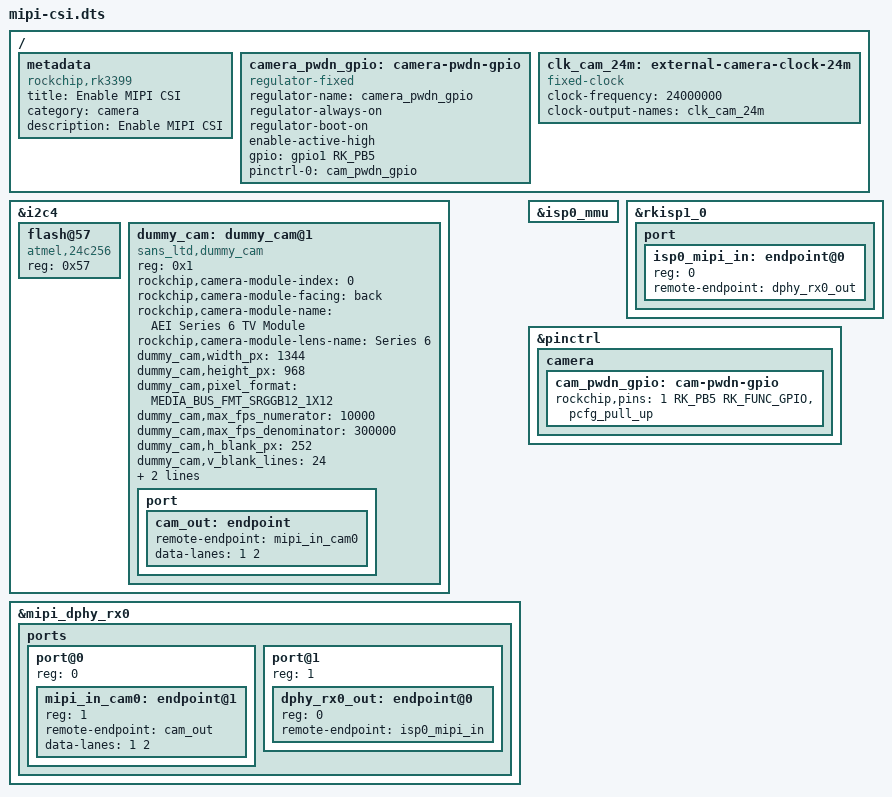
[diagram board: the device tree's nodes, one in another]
/dts-v1/;
/plugin/;

#include <dt-bindings/gpio/gpio.h>
#include <dt-bindings/pinctrl/rockchip.h>
#include <dt-bindings/display/media-bus-format.h>

/ {
	metadata {
		title ="Enable MIPI CSI";
		compatible = "rockchip,rk3399";
		category = "camera";
		description = "Enable MIPI CSI";
	};


	fragment@0 {
		target-path = "/";

		__overlay__ {

			camera_pwdn_gpio: camera-pwdn-gpio {
				status = "okay";
				compatible = "regulator-fixed";
				regulator-name = "camera_pwdn_gpio";
				regulator-always-on;
				regulator-boot-on;
				enable-active-high;
				gpio = <&gpio1 RK_PB5 GPIO_ACTIVE_HIGH>;
				pinctrl-names = "default";
				pinctrl-0 = <&cam_pwdn_gpio>;
			};

			clk_cam_24m: external-camera-clock-24m {
				status = "okay";
				compatible = "fixed-clock";
				clock-frequency = <24000000>;
				clock-output-names = "clk_cam_24m";
				#clock-cells = <0>;
			};
		};
	};

	fragment@1 {
		target = <&i2c4>;

		__overlay__ {
			status = "okay";
			#address-cells = <1>;
			#size-cells = <0>;

/*
			camera_imx219: camera-imx219@10 {
				status = "okay";
				compatible = "sony,imx219";
				reg = <0x10>;

				clocks = <&clk_cam_24m>;
				clock-names = "xvclk";

				rockchip,camera-module-index = <0>;
				rockchip,camera-module-facing = "back";
				rockchip,camera-module-name = "rpi-camera-v2";
				rockchip,camera-module-lens-name = "default";

				port {
					ucam_out0: endpoint {
						remote-endpoint = <&mipi_in_ucam0>;
						data-lanes = <1 2>;
					};
				};
			};
*/
			flash@57 {
                compatible = "atmel,24c256";
                reg = <0x57>;
        	};


			dummy_cam: dummy_cam@1 {
				// dummy sensor for preisp, sensor use this driver when communicating directly with rk1608
				// sensor and AP communication use the corresponding sensor driver 
				compatible = "sans_ltd,dummy_cam";
				status = "okay";
				reg = <0x1>;

				rockchip,camera-module-index = <0>;
				rockchip,camera-module-facing = "back";
				rockchip,camera-module-name = "AEI Series 6 TV Module";
				rockchip,camera-module-lens-name = "Series 6";

				dummy_cam,width_px = <1344>;
				dummy_cam,height_px = <968>;
				// See media-bus-format.h
				dummy_cam,pixel_format = <MEDIA_BUS_FMT_SRGGB12_1X12>;
				dummy_cam,max_fps_numerator = <10000>;
				dummy_cam,max_fps_denominator = <300000>;

				dummy_cam,h_blank_px = <252>;
				dummy_cam,v_blank_lines = <24>;
				dummy_cam,link_freq_hz = <175000000>;
				dummy_cam,pixel_rate_hz = <87500000>;

				port {
					cam_out: endpoint {
						remote-endpoint = <&mipi_in_cam0>;//sensor output port
						data-lanes = <1 2>;
					};
				};
			};
		};
	};


	fragment@2 {
		target = <&mipi_dphy_rx0>;

		__overlay__ {
			status = "okay";

			ports {
				#address-cells = <1>;
				#size-cells = <0>;

				port@0 {
					reg = <0>;
					#address-cells = <1>;
					#size-cells = <0>;

					mipi_in_cam0: endpoint@1 {
						reg = <1>;
						remote-endpoint = <&cam_out>;
						data-lanes = <1 2>;
					};
				};

				port@1 {
					reg = <1>;
					#address-cells = <1>;
					#size-cells = <0>;

					dphy_rx0_out: endpoint@0 {
						reg = <0>;
						remote-endpoint = <&isp0_mipi_in>;
					};
				};			

/*				
				port@0 {
					reg = <0>;
					#address-cells = <1>;
					#size-cells = <0>;

					dphy_rx0_out: endpoint@0 {
						reg = <0>;
						remote-endpoint = <&isp0_mipi_in>;
					};
				};
*/				
			};
		};
	};

	fragment@3 {
		target = <&isp0_mmu>;

		__overlay__ {
			status = "okay";
		};
	};

	fragment@4 {
		target = <&rkisp1_0>;

		__overlay__ {
			status = "okay";

			port {
				#address-cells = <1>;
				#size-cells = <0>;

				isp0_mipi_in: endpoint@0 {
					reg = <0>;
					remote-endpoint = <&dphy_rx0_out>;
				};
			};
		};
	};


	fragment@5 {
		target = <&pinctrl>;

		__overlay__ {
			camera {
				cam_pwdn_gpio: cam-pwdn-gpio {
					rockchip,pins = <1 RK_PB5 RK_FUNC_GPIO &pcfg_pull_up>;
				};
			};
		};
	};
};
